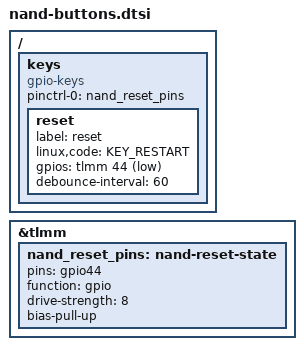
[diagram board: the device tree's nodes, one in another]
#include <dt-bindings/input/input.h>

/ {
	keys {
		compatible = "gpio-keys";
		pinctrl-0 = <&nand_reset_pins>;
		pinctrl-names = "default";
		reset {
			label = "reset";
			linux,code = <KEY_RESTART>;
			gpios = <&tlmm 44 GPIO_ACTIVE_LOW>;
			debounce-interval = <60>;
		};
	};
};

&tlmm {
	nand_reset_pins: nand-reset-state {
		pins = "gpio44";
		function = "gpio";
		drive-strength = <8>;
		bias-pull-up;
	};
};
